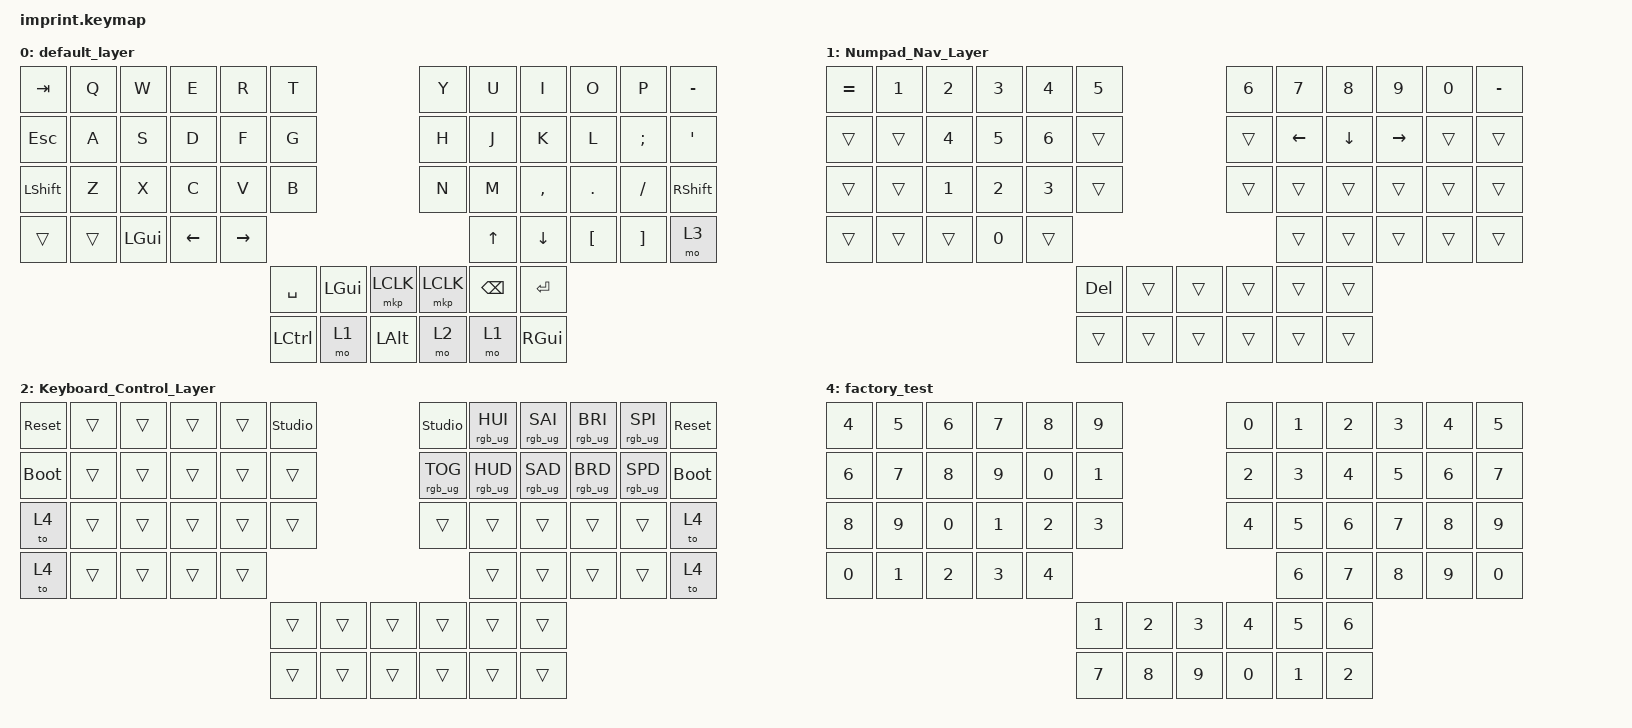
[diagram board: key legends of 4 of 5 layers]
#include <input/processors.dtsi>
#include <dt-bindings/zmk/input_transform.h>
#include <behaviors.dtsi>
#include <dt-bindings/zmk/bt.h>
#include <dt-bindings/zmk/keys.h>
#include <dt-bindings/zmk/pointing.h>
#include <dt-bindings/zmk/rgb.h>

/ {
    chosen { zmk,matrix-transform = &imprint_letters_only_full_bottom_row;
    };
    keymap {
        compatible = "zmk,keymap";

        default_layer {
            bindings = <
 &kp TAB    &kp Q     &kp W     &kp E     &kp R   &kp T                                          &kp Y       &kp U      &kp I     &kp O    &kp P    &kp MINUS 
 &kp ESC    &kp A     &kp S     &kp D     &kp F   &kp G                                          &kp H       &kp J      &kp K     &kp L    &kp SEMI &kp SQT
 &kp LSHFT  &kp Z     &kp X     &kp C     &kp V   &kp B                                          &kp N       &kp M      &kp COMMA &kp DOT  &kp FSLH &kp RSHFT
&trans     &trans  &kp LGUI  &kp LEFT  &kp RIGHT                                                             &kp UP    &kp DOWN   &kp LBKT  &kp RBKT    &mo 3
                                                  &kp SPACE  &kp LGUI &mkp LCLK    &mkp LCLK &kp BSPC &kp RET
                                                  &kp LCTL &mo 1   &kp LALT      &mo 2  &mo 1  &kp RGUI
            >;
        };

        Numpad_Nav_Layer {
            bindings = <
 &kp EQUAL  &kp N1  &kp N2  &kp N3  &kp N4  &kp N5                                     &kp N6  &kp N7 &kp N8   &kp N9   &kp N0  &kp MINUS
 &trans  &trans  &kp N4  &kp N5  &kp N6  &trans                                     &trans  &kp LEFT &kp DOWN &kp RIGHT &trans  &trans
 &trans  &trans  &kp N1  &kp N2  &kp N3  &trans                                     &trans  &trans   &trans   &trans    &trans  &trans
&trans  &trans  &trans  &kp N0  &trans                            &trans    &trans    &trans     &trans  &trans
                                      &kp DEL  &trans &trans       &trans  &trans &trans
                                      &trans  &trans &trans       &trans  &trans &trans
            >;
        };

        Keyboard_Control_Layer {
            bindings = <
 &sys_reset      &trans  &trans  &trans  &trans  &studio_unlock                             &studio_unlock &rgb_ug RGB_HUI  &rgb_ug RGB_SAI &rgb_ug RGB_BRI &rgb_ug RGB_SPI &sys_reset
 &bootloader &trans  &trans  &trans  &trans  &trans                                     &rgb_ug RGB_TOG  &rgb_ug RGB_HUD  &rgb_ug RGB_SAD &rgb_ug RGB_BRD &rgb_ug RGB_SPD &bootloader
 &to 4      &trans  &trans  &trans  &trans  &trans                                     &trans         &trans           &trans          &trans          &trans          &to 4
&to 4        &trans        &trans        &trans        &trans                                        &trans           &trans           &trans           &trans           &to 4
                                         &trans  &trans &trans        &trans &trans &trans
                                         &trans  &trans &trans        &trans &trans &trans
            >;
        };

        Auto_Mouse_Layer {
            bindings = <
 &trans  &trans  &trans  &trans  &trans  &trans                                     &trans  &trans  &trans  &trans  &trans  &trans
 &trans  &trans  &mkp RCLK  &mkp MCLK  &mkp LCLK  &trans                            &trans  &trans  &trans  &trans  &trans  &trans
 &trans  &trans  &trans  &trans  &trans  &trans                                     &trans  &trans  &trans  &trans  &trans  &trans
 &trans  &trans  &trans  &trans  &trans  &trans                                     &trans  &trans  &trans  &trans  &trans  &trans
                                         &trans  &trans &trans        &trans &trans &trans
                                         &trans  &trans &trans        &trans &trans &trans
            >;
        };

        factory_test {
            bindings = <
&kp N4  &kp N5  &kp N6  &kp N7  &kp N8  &kp N9            &kp N0  &kp N1  &kp N2  &kp N3  &kp N4  &kp N5
&kp N6  &kp N7  &kp N8  &kp N9  &kp N0  &kp N1            &kp N2  &kp N3  &kp N4  &kp N5  &kp N6  &kp N7
&kp N8  &kp N9  &kp N0  &kp N1  &kp N2  &kp N3            &kp N4  &kp N5  &kp N6  &kp N7  &kp N8  &kp N9
&kp N0  &kp N1  &kp N2  &kp N3  &kp N4                            &kp N6  &kp N7  &kp N8  &kp N9  &kp N0
                                &kp N1  &kp N2  &kp N3    &kp N4  &kp N5  &kp N6
                                &kp N7  &kp N8  &kp N9    &kp N0  &kp N1  &kp N2
            >;
        };
    };
};

// right hand trackball configuration

&trackball_peripheral_listener {
    input-processors = <&zip_xy_scaler 1 1>;

    scroller {
        layers = <1>;
        input-processors =      
            // disable horizontal scroll
            <&zip_x_scaler 1 1000000>,
            <&zip_y_scaler 1 10>,
            <&zip_xy_to_scroll_mapper>,
            <&zip_scroll_scaler 1 5>;
    };
};

//left hand trackball configuration

&trackball_central_listener {
    input-processors =
        // multiply sensitivity by 1, divide by 3 (make it slower for scrolling),
        <&zip_xy_scaler 1 3>,
        // make this trackball output scrolling events by default instead of cursor movement,
        <&zip_xy_to_scroll_mapper>,
        // invert vertical scrolling so that the view moves in the same direction as the top of the trackball.,
        <&zip_scroll_transform INPUT_TRANSFORM_Y_INVERT>;
};
